# STM32H733 register map
File version: 1.2
CPU: CM7 r0p1, little endian, MPU, FPU, 4 interrupt priority bits
Registers are 32-bit, read-write, reset 0x0 unless marked. A register's access mark holds for its fields unless they carry their own. Offsets are from the block's base; [hi:lo] are bit positions; lines under a group give offsets from that group; {n}, {i} and the like mark numbered series; 'fields as' and 'values as' point back to an identical list; <NAME> marks a mode.

## ADC1 — Analog to Digital Converter
Base 0x40022000
Same registers: ADC2 0x40022100
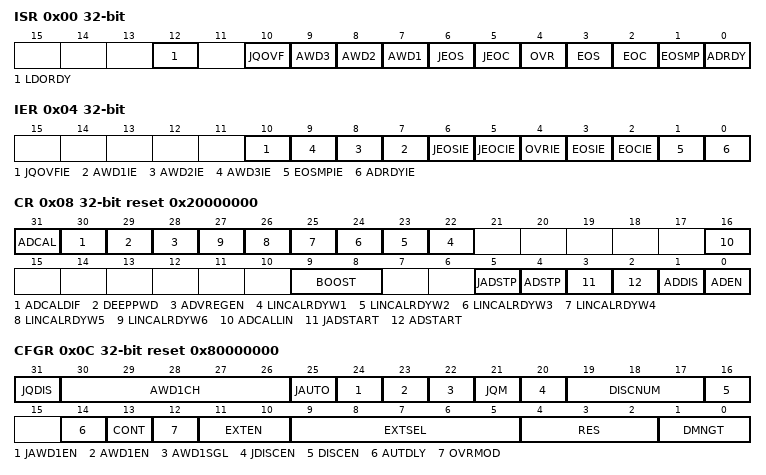
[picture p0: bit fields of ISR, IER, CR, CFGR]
0x00 ISR access per field — ADC interrupt and status register
  [12] LDORDY ro — ADC LDO output voltage ready bit This bit is set and cleared by hardware. It indicates that the ADC internal LDO output is ready and that the ADC can be enabled or calibrated. Note: Refer to for the availability of the LDO regulator.
  [10] JQOVF rw write-1-clears — Injected context queue overflow This bit is set by hardware when an Overflow of the Injected Queue of Context occurs. It is cleared by software writing 1 to it. Refer to for more information.
    on read: 0=NoOverflow (No injected context queue overflow has occurred); 1=Overflow (Injected context queue overflow has occurred) | on write: 1=Clear injected context queue overflow flag
  [n+6] AWD{n} (n=1..3) rw write-1-clears — Analog watchdog {n} flag
    on read: 0=NoEvent (No analog watchdog event occurred); 1=Event (Analog watchdog event occurred) | on write: 1=Clear analog watchdog event occurred flag
  [6] JEOS rw write-1-clears — Injected channel end of sequence flag This bit is set by hardware at the end of the conversions of all injected channels in the group. It is cleared by software writing 1 to it.
    on read: 0=NotComplete (Injected sequence is not complete); 1=Complete (Injected sequence complete) | on write: 1=Clear Injected sequence complete flag
  [5] JEOC rw write-1-clears — Injected channel end of conversion flag This bit is set by hardware at the end of each injected conversion of a channel when a new data is available in the corresponding ADC_JDRy register. It is cleared by software writing 1 to it or by reading the corresponding ADC_JDRy register
    on read: 0=NotComplete (Injected conversion is not complete); 1=Complete (Injected conversion complete) | on write: 1=Clear injected conversion complete flag
  [4] OVR rw write-1-clears — ADC overrun This bit is set by hardware when an overrun occurs on a regular channel, meaning that a new conversion has completed while the EOC flag was already set. It is cleared by software writing 1 to it.
    on read: 0=No overrun occurred; 1=Overrun occurred | on write: 1=Clear overrun occurred flag
  [3] EOS rw write-1-clears — End of regular sequence flag This bit is set by hardware at the end of the conversions of a regular sequence of channels. It is cleared by software writing 1 to it.
    on read: 0=NotComplete (Regular sequence is not complete); 1=Complete (Regular sequence complete) | on write: 1=Clear regular sequence complete flag
  [2] EOC rw write-1-clears — End of conversion flag This bit is set by hardware at the end of each regular conversion of a channel when a new data is available in the ADC_DR register. It is cleared by software writing 1 to it or by reading the ADC_DR register
    on read: 0=NotComplete (Regular conversion is not complete); 1=Complete (Regular conversion complete) | on write: 1=Clear regular conversion complete flag
  [1] EOSMP rw write-1-clears — End of sampling flag This bit is set by hardware during the conversion of any channel (only for regular channels), at the end of the sampling phase.
    on read: 0=NotEnded (End of sampling phase no yet reached); 1=Ended (End of sampling phase reached) | on write: 1=Clear end of sampling phase reached flag
  [0] ADRDY rw write-1-clears — ADC ready This bit is set by hardware after the ADC has been enabled (bit ADEN=1) and when the ADC reaches a state where it is ready to accept conversion requests. It is cleared by software writing 1 to it.
    on read: 0=NotReady (ADC is not ready to start conversion); 1=Ready (ADC is ready to start conversion) | on write: 1=Clear ADC is ready to start conversion flag
0x04 IER — ADC interrupt enable register
  [10] JQOVFIE — Injected context queue overflow interrupt enable This bit is set and cleared by software to enable/disable the Injected Context Queue Overflow interrupt. Note: The software is allowed to write this bit only when JADSTART=0 (which ensures that no injected conversion is ongoing).
    0=Disabled (Injected context queue overflow interrupt disabled); 1=Enabled (Injected context queue overflow interrupt enabled)
  [n+6] AWD{n}IE (n=1..3) — Analog watchdog {n} interrupt enable
    0=Disabled (Analog watchdog interrupt disabled); 1=Enabled (Analog watchdog interrupt enabled)
  [6] JEOSIE — End of injected sequence of conversions interrupt enable This bit is set and cleared by software to enable/disable the end of injected sequence of conversions interrupt. Note: The software is allowed to write this bit only when JADSTART=0 (which ensures that no injected conversion is ongoing).
    0=Disabled (End of injected sequence interrupt disabled); 1=Enabled (End of injected sequence interrupt enabled)
  [5] JEOCIE — End of injected conversion interrupt enable This bit is set and cleared by software to enable/disable the end of an injected conversion interrupt. Note: The software is allowed to write this bit only when JADSTART is cleared to 0 (no injected conversion is ongoing).
    0=Disabled (End of injected conversion interrupt disabled); 1=Enabled (End of injected conversion interrupt enabled)
  [4] OVRIE — Overrun interrupt enable This bit is set and cleared by software to enable/disable the Overrun interrupt of a regular conversion. Note: The software is allowed to write this bit only when ADSTART=0 (which ensures that no regular conversion is ongoing).
    0=Disabled (Overrun interrupt disabled); 1=Enabled (Overrun interrupt enabled)
  [3] EOSIE — End of regular sequence of conversions interrupt enable This bit is set and cleared by software to enable/disable the end of regular sequence of conversions interrupt. Note: The software is allowed to write this bit only when ADSTART=0 (which ensures that no regular conversion is ongoing).
    0=Disabled (End of regular sequence interrupt disabled); 1=Enabled (End of regular sequence interrupt enabled)
  [2] EOCIE — End of regular conversion interrupt enable This bit is set and cleared by software to enable/disable the end of a regular conversion interrupt. Note: The software is allowed to write this bit only when ADSTART=0 (which ensures that no regular conversion is ongoing).
    0=Disabled (End of regular conversion interrupt disabled); 1=Enabled (End of regular conversion interrupt enabled)
  [1] EOSMPIE — End of sampling flag interrupt enable for regular conversions This bit is set and cleared by software to enable/disable the end of the sampling phase interrupt for regular conversions. Note: The software is allowed to write this bit only when ADSTART=0 (which ensures that no regular conversion is ongoing).
    0=Disabled (End of regular conversion sampling phase interrupt disabled); 1=Enabled (End of regular conversion sampling phase interrupt enabled)
  [0] ADRDYIE — ADC ready interrupt enable This bit is set and cleared by software to enable/disable the ADC Ready interrupt. Note: The software is allowed to write this bit only when ADSTART=0 and JADSTART=0 (which ensures that no conversion is ongoing).
    0=Disabled (ADC ready interrupt disabled); 1=Enabled (ADC ready interrupt enabled)
0x08 CR reset 0x20000000 — ADC control register
  [31] ADCAL write-1-sets — ADC calibration This bit is set by software to start the calibration of the ADC. Program first the bit ADCALDIF to determine if this calibration applies for single-ended or differential inputs mode. It is cleared by hardware after calibration is complete. Note: The software is allowed to launch a calibration by setting ADCAL only when ADEN=0. The software is allowed to update the calibration factor by writing ADC_CALFACT only when ADEN=1 and ADSTART=0 and JADSTART=0 (ADC enabled and no conversion is ongoing)
    on read: 0=NotCalibrating (ADC calibration either not yet performed or completed); 1=Calibrating (ADC calibration in progress) | on write: 1=StartCalibration (Start the ADC calibration sequence)
  [30] ADCALDIF — Differential mode for calibration This bit is set and cleared by software to configure the single-ended or differential inputs mode for the calibration. Note: The software is allowed to write this bit only when the ADC is disabled and is not calibrating (ADCAL=0, JADSTART=0, JADSTP=0, ADSTART=0, ADSTP=0, ADDIS=0 and ADEN=0).
    0=SingleEnded (Calibration for single-ended mode); 1=Differential (Calibration for differential mode)
  [29] DEEPPWD — Deep-power-down enable This bit is set and cleared by software to put the ADC in deep-power-down mode. Note: The software is allowed to write this bit only when the ADC is disabled (ADCAL=0, JADSTART=0, JADSTP=0, ADSTART=0, ADSTP=0, ADDIS=0 and ADEN=0).
    0=PowerUp (ADC not in deep power down); 1=PowerDown (ADC in deep power down)
  [28] ADVREGEN — ADC voltage regulator enable This bits is set by software to enable the ADC voltage regulator. Before performing any operation such as launching a calibration or enabling the ADC, the ADC voltage regulator must first be enabled and the software must wait for the regulator start-up time. For more details about the ADC voltage regulator enable and disable sequences, refer to (ADVREGEN). The software can program this bitfield only when the ADC is disabled (ADCAL=0, JADSTART=0, ADSTART=0, ADSTP=0, ADDIS=0 and ADEN=0).
    0=Disabled (ADC voltage regulator disabled); 1=Enabled (ADC voltage regulator enabled)
  [n+21] LINCALRDYW{n} (n=1..6) — Linearity calibration ready Word {n}
    0=Reset (LINCALFACT Word Read); 1=Set (LINCALFACT Word Write)
  [16] ADCALLIN — Linearity calibration This bit is set and cleared by software to enable the Linearity calibration. Note: The software is allowed to write this bit only when the ADC is disabled and is not calibrating (ADCAL=0, JADSTART=0, JADSTP=0, ADSTART=0, ADSTP=0, ADDIS=0 and ADEN=0).
    0=NoLinearity (ADC calibration without linearaity calibration); 1=Linearity (ADC calibration with linearaity calibration)
  [9:8] BOOST — Boost mode control This bitfield is set and cleared by software to enable/disable the Boost mode. Note: The software is allowed to write this bit only when ADSTART=0 and JADSTART=0 (which ensures that no conversion is ongoing). When dual mode is enabled (bits DAMDF of ADCx_CCR register are not equal to zero), the BOOST bitfield of the slave ADC is no more writable and its content must be equal to the master ADC BOOST bitfield.
    0=LT6_25 (Boost mode used when ADC clock ≤ 6.25 MHz); 1=LT12_5 (Boost mode used when 6.25 MHz < ADC clock ≤ 12.5 MHz); 2=LT25 (Boost mode used when 12.5 MHz < ADC clock ≤ 25.0 MHz); 3=LT50 (Boost mode used when 25.0 MHz < ADC clock ≤ 50.0 MHz)
  [5] JADSTP write-1-sets — ADC stop of injected conversion command This bit is set by software to stop and discard an ongoing injected conversion (JADSTP Command). It is cleared by hardware when the conversion is effectively discarded and the ADC injected sequence and triggers can be re-configured. The ADC is then ready to accept a new start of injected conversions (JADSTART command). Note: The software is allowed to set JADSTP only when JADSTART=1 and ADDIS=0 (ADC is enabled and eventually converting an injected conversion and there is no pending request to disable the ADC). In auto-injection mode (JAUTO=1), setting ADSTP bit aborts both regular and injected conversions (do not use JADSTP)
    on read: 0=NotStopping (No stop command active); 1=Stopping (ADC stopping conversion) | on write: 1=StopConversion (Stop the active conversion)
  [4] ADSTP write-1-sets — ADC stop of regular conversion command This bit is set by software to stop and discard an ongoing regular conversion (ADSTP Command). It is cleared by hardware when the conversion is effectively discarded and the ADC regular sequence and triggers can be re-configured. The ADC is then ready to accept a new start of regular conversions (ADSTART command). Note: The software is allowed to set ADSTP only when ADSTART=1 and ADDIS=0 (ADC is enabled and eventually converting a regular conversion and there is no pending request to disable the ADC). In auto-injection mode (JAUTO=1), setting ADSTP bit aborts both regular and injected conversions (do not use JADSTP). In dual ADC regular simultaneous mode and interleaved mode, the bit ADSTP of the master ADC must be used to stop regular conversions. The other ADSTP bit is inactive.
    values as JADSTP
  [3] JADSTART write-1-sets — ADC start of injected conversion This bit is set by software to start ADC conversion of injected channels. Depending on the configuration bits JEXTEN, a conversion will start immediately (software trigger configuration) or once an injected hardware trigger event occurs (hardware trigger configuration). It is cleared by hardware: in single conversion mode when software trigger is selected (JEXTSEL=0x0): at the assertion of the End of Injected Conversion Sequence (JEOS) flag. in all cases: after the execution of the JADSTP command, at the same time that JADSTP is cleared by hardware. Note: The software is allowed to set JADSTART only when ADEN=1 and ADDIS=0 (ADC is enabled and there is no pending request to disable the ADC). In auto-injection mode (JAUTO=1), regular and auto-injected conversions are started by setting bit ADSTART (JADSTART must be kept cleared)
    on read: 0=NotActive (No conversion ongoing); 1=Active (ADC operating and may be converting) | on write: 1=StartConversion (Start the ADC conversion (may be delayed for hardware triggers))
  [2] ADSTART write-1-sets — ADC start of regular conversion This bit is set by software to start ADC conversion of regular channels. Depending on the configuration bits EXTEN, a conversion will start immediately (software trigger configuration) or once a regular hardware trigger event occurs (hardware trigger configuration). It is cleared by hardware: in single conversion mode (CONT=0, DISCEN=0) when software trigger is selected (EXTEN=0x0): at the assertion of the End of Regular Conversion Sequence (EOS) flag. In discontinuous conversion mode (CONT=0, DISCEN=1), when the software trigger is selected (EXTEN=0x0): at the end of conversion (EOC) flag. in all other cases: after the execution of the ADSTP command, at the same time that ADSTP is cleared by hardware. Note: The software is allowed to set ADSTART only when ADEN=1 and ADDIS=0 (ADC is enabled and there is no pending request to disable the ADC) In auto-injection mode (JAUTO=1), regular and auto-injected conversions are started by setting bit ADSTART (JADSTART must be kept cleared)
    values as JADSTART
  [1] ADDIS write-1-sets — ADC disable command This bit is set by software to disable the ADC (ADDIS command) and put it into power-down state (OFF state). It is cleared by hardware once the ADC is effectively disabled (ADEN is also cleared by hardware at this time). Note: The software is allowed to set ADDIS only when ADEN=1 and both ADSTART=0 and JADSTART=0 (which ensures that no conversion is ongoing)
    on read: 0=NotDisabling (No disable command active); 1=Disabling (ADC disabling) | on write: 1=Disable the ADC
  [0] ADEN write-1-sets — ADC enable control This bit is set by software to enable the ADC. The ADC will be effectively ready to operate once the flag ADRDY has been set. It is cleared by hardware when the ADC is disabled, after the execution of the ADDIS command. Note: The software is allowed to set ADEN only when all bits of ADC_CR registers are 0 (ADCAL=0, JADSTART=0, ADSTART=0, ADSTP=0, ADDIS=0 and ADEN=0) except for bit ADVREGEN which must be 1 (and the software must have wait for the startup time of the voltage regulator)
    on read: 0=Disabled (ADC disabled); 1=Enabled (ADC enabled) | on write: 1=Enabled (Enable the ADC)
0x0C CFGR reset 0x80000000 — ADC configuration register
  [31] JQDIS — Injected Queue disable These bits are set and cleared by software to disable the Injected Queue mechanism: Note: The software is allowed to write this bit only when ADSTART=0 and JADSTART=0 (which ensures that no regular nor injected conversion is ongoing). A set or reset of JQDIS bit causes the injected queue to be flushed and the JSQR register is cleared.
    0=Enabled (Injected Queue enabled); 1=Disabled (Injected Queue disabled)
  [30:26] AWD1CH range 0..19 — Analog watchdog 1 channel selection These bits are set and cleared by software. They select the input channel to be guarded by the analog watchdog. ..... others: Reserved, must not be used Note: The channel selected by AWD1CH must be also selected into the SQRi or JSQRi registers. The software is allowed to write these bits only when ADSTART=0 and JADSTART=0 (which ensures that no conversion is ongoing).
  [25] JAUTO — Automatic injected group conversion This bit is set and cleared by software to enable/disable automatic injected group conversion after regular group conversion. Note: The software is allowed to write this bit only when ADSTART=0 and JADSTART=0 (which ensures that no regular nor injected conversion is ongoing). When dual mode is enabled (DAMDF bits in ADCx_CCR register are not equal to zero), the bit JAUTO of the slave ADC is no more writable and its content is equal to the bit JAUTO of the master ADC.
    0=Disabled (Automatic injected group conversion disabled); 1=Enabled (Automatic injected group conversion enabled)
  [24] JAWD1EN — Analog watchdog 1 enable on injected channels This bit is set and cleared by software Note: The software is allowed to write this bit only when JADSTART=0 (which ensures that no injected conversion is ongoing).
    0=Disabled (Analog watchdog 1 disabled on injected channels); 1=Enabled (Analog watchdog 1 enabled on injected channels)
  [23] AWD1EN — Analog watchdog 1 enable on regular channels This bit is set and cleared by software Note: The software is allowed to write this bit only when ADSTART=0 (which ensures that no regular conversion is ongoing).
    0=Disabled (Analog watchdog 1 disabled on regular channels); 1=Enabled (Analog watchdog 1 enabled on regular channels)
  [22] AWD1SGL — Enable the watchdog 1 on a single channel or on all channels This bit is set and cleared by software to enable the analog watchdog on the channel identified by the AWD1CH[4:0] bits or on all the channels Note: The software is allowed to write this bit only when ADSTART=0 and JADSTART=0 (which ensures that no conversion is ongoing).
    0=All (Analog watchdog 1 enabled on all channels); 1=Single (Analog watchdog 1 enabled on single channel selected in AWD1CH)
  [21] JQM — JSQR queue mode This bit is set and cleared by software. It defines how an empty Queue is managed. Refer to for more information. Note: The software is allowed to write this bit only when JADSTART=0 (which ensures that no injected conversion is ongoing). When dual mode is enabled (DAMDF bits in ADCx_CCR register are not equal to zero), the bit JQM of the slave ADC is no more writable and its content is equal to the bit JQM of the master ADC.
    0=Mode0 (JSQR Mode 0: Queue maintains the last written configuration into JSQR); 1=Mode1 (JSQR Mode 1: An empty queue disables software and hardware triggers of the injected sequence)
  [20] JDISCEN — Discontinuous mode on injected channels This bit is set and cleared by software to enable/disable discontinuous mode on the injected channels of a group. Note: The software is allowed to write this bit only when JADSTART=0 (which ensures that no injected conversion is ongoing). It is not possible to use both auto-injected mode and discontinuous mode simultaneously: the bits DISCEN and JDISCEN must be kept cleared by software when JAUTO is set. When dual mode is enabled (bits DAMDF of ADCx_CCR register are not equal to zero), the bit JDISCEN of the slave ADC is no more writable and its content is equal to the bit JDISCEN of the master ADC.
    0=Disabled (Discontinuous mode on injected channels disabled); 1=Enabled (Discontinuous mode on injected channels enabled)
  [19:17] DISCNUM — Discontinuous mode channel count These bits are written by software to define the number of regular channels to be converted in discontinuous mode, after receiving an external trigger. ... Note: The software is allowed to write these bits only when ADSTART=0 (which ensures that no regular conversion is ongoing). When dual mode is enabled (DAMDF bits in ADCx_CCR register are not equal to zero), the bits DISCNUM[2:0] of the slave ADC are no more writable and their content is equal to the bits DISCNUM[2:0] of the master ADC.
  [16] DISCEN — Discontinuous mode for regular channels This bit is set and cleared by software to enable/disable Discontinuous mode for regular channels. Note: It is not possible to have both discontinuous mode and continuous mode enabled: it is forbidden to set both DISCEN=1 and CONT=1. It is not possible to use both auto-injected mode and discontinuous mode simultaneously: the bits DISCEN and JDISCEN must be kept cleared by software when JAUTO is set. The software is allowed to write this bit only when ADSTART=0 (which ensures that no regular conversion is ongoing). When dual mode is enabled (DAMDF bits in ADCx_CCR register are not equal to zero), the bit DISCEN of the slave ADC is no more writable and its content is equal to the bit DISCEN of the master ADC.
    0=Disabled (Discontinuous mode on regular channels disabled); 1=Enabled (Discontinuous mode on regular channels enabled)
  [14] AUTDLY — Delayed conversion mode This bit is set and cleared by software to enable/disable the Auto Delayed Conversion mode.. Note: The software is allowed to write this bit only when ADSTART=0 and JADSTART=0 (which ensures that no conversion is ongoing). When dual mode is enabled (DAMDF bits in ADCx_CCR register are not equal to zero), the bit AUTDLY of the slave ADC is no more writable and its content is equal to the bit AUTDLY of the master ADC.
    0=Off (Auto delayed conversion mode off); 1=On (Auto delayed conversion mode on)
  [13] CONT — Single / continuous conversion mode for regular conversions This bit is set and cleared by software. If it is set, regular conversion takes place continuously until it is cleared. Note: It is not possible to have both discontinuous mode and continuous mode enabled: it is forbidden to set both DISCEN=1 and CONT=1. The software is allowed to write this bit only when ADSTART=0 (which ensures that no regular conversion is ongoing). When dual mode is enabled (DAMDF bits in ADCx_CCR register are not equal to zero), the bit CONT of the slave ADC is no more writable and its content is equal to the bit CONT of the master ADC.
    0=Single conversion mode; 1=Continuous conversion mode
  [12] OVRMOD — Overrun Mode This bit is set and cleared by software and configure the way data overrun is managed. Note: The software is allowed to write this bit only when ADSTART=0 (which ensures that no regular conversion is ongoing).
    0=Preserve DR register when an overrun is detected; 1=Overwrite DR register when an overrun is detected
  [11:10] EXTEN — External trigger enable and polarity selection for regular channels These bits are set and cleared by software to select the external trigger polarity and enable the trigger of a regular group. Note: The software is allowed to write these bits only when ADSTART=0 (which ensures that no regular conversion is ongoing).
    0=Disabled (Trigger detection disabled); 1=RisingEdge (Trigger detection on the rising edge); 2=FallingEdge (Trigger detection on the falling edge); 3=BothEdges (Trigger detection on both the rising and falling edges)
  [9:5] EXTSEL — External trigger selection for regular group These bits select the external event used to trigger the start of conversion of a regular group: ... Note: The software is allowed to write these bits only when ADSTART=0 (which ensures that no regular conversion is ongoing).
    0=TIM1_CC1 (Timer 1 CC1 event); 1=TIM1_CC2 (Timer 1 CC2 event); 2=TIM1_CC3 (Timer 1 CC3 event); 3=TIM2_CC2 (Timer 2 CC2 event); 4=TIM3_TRGO (Timer 3 TRGO event); 5=TIM4_CC4 (Timer 4 CC4 event); 6=EXTI11 (EXTI line 11); 7=TIM8_TRGO (Timer 8 TRGO event); 8=TIM8_TRGO2 (Timer 8 TRGO2 event); 9=TIM1_TRGO (Timer 1 TRGO event); 10=TIM1_TRGO2 (Timer 1 TRGO2 event); 11=TIM2_TRGO (Timer 2 TRGO event); 12=TIM4_TRGO (Timer 4 TRGO event); 13=TIM6_TRGO (Timer 6 TRGO event); 14=TIM15_TRGO (Timer 15 TRGO event); 15=TIM3_CC4 (Timer 3 CC4 event); 16=HRTIM1_ADCTRG1 (HRTIM1_ADCTRG1 event); 17=HRTIM1_ADCTRG3 (HRTIM1_ADCTRG3 event); 18=LPTIM1_OUT (LPTIM1_OUT event); 19=LPTIM2_OUT (LPTIM2_OUT event); 20=LPTIM3_OUT (LPTIM3_OUT event)
  [4:2] RES — Data resolution These bits are written by software to select the resolution of the conversion. Others: Reserved, must not be used. Note: The software is allowed to write these bits only when ADSTART=0 and JADSTART=0 (which ensures that no conversion is ongoing).
    0=SixteenBit (16-bit resolution); 1=FourteenBit (14-bit resolution in legacy mode (not optimized power consumption)); 2=TwelveBit (12-bit resolution in legacy mode (not optimized power consumption)); 3=TenBit (10-bit resolution); 5=FourteenBitV (14-bit resolution); 6=TwelveBitV (12-bit resolution); 7=EightBit (8-bit resolution)
  [1:0] DMNGT — Data Management configuration This bit is set and cleared by software to select how ADC interface output data are managed. Note: The software is allowed to write this bit only when ADSTART=0 and JADSTART=0 (which ensures that no conversion is ongoing). In dual-ADC modes, this bit is not relevant and replaced by control bit DAMDF of the ADCx_CCR register.
    0=DR (Store output data in DR only); 1=DMA One Shot Mode selected; 2=DFSDM (DFSDM mode selected); 3=DMA Circular Mode selected
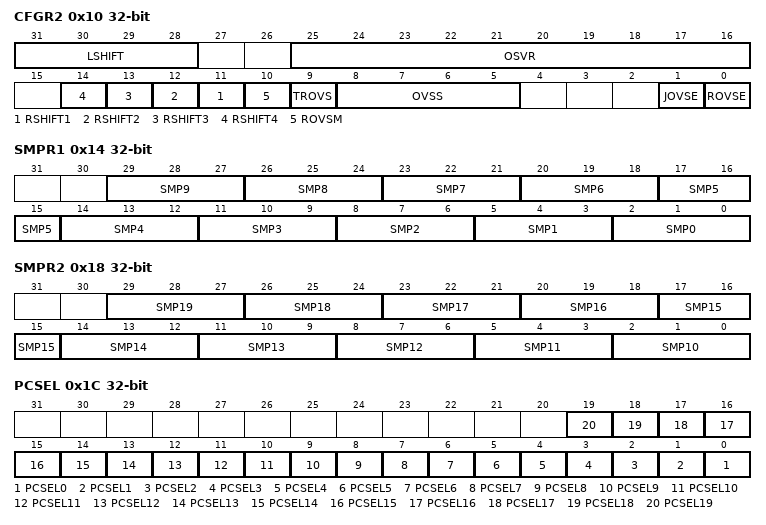
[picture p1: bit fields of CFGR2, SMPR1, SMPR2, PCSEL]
0x10 CFGR2 — ADC configuration register 2
  [31:28] LSHIFT — Left shift factor This bitfield is set and cleared by software to define the left shifting applied to the final result with or without oversampling. Note: The software is allowed to write this bit only when ADSTART=0 (which ensures that no conversion is ongoing).
  [25:16] OSVR — Oversampling ratio This bitfield is set and cleared by software to define the oversampling ratio. 2: 3x ... 1023: 1024x Note: The software is allowed to write this bit only when ADSTART=0 (which ensures that no conversion is ongoing).
  [n+10] RSHIFT{n} (n=1..4) — Right-shift data after Offset {n} correction
    0=Disabled (Right-shifting disabled); 1=Enabled (Data is right-shifted 1-bit)
  [10] ROVSM — Regular Oversampling mode This bit is set and cleared by software to select the regular oversampling mode. Note: The software is allowed to write this bit only when ADSTART=0 (which ensures that no conversion is ongoing).
    0=Continued (Oversampling is temporary stopped and continued after injection sequence); 1=Resumed (Oversampling is aborted and resumed from start after injection sequence)
  [9] TROVS — Triggered Regular Oversampling This bit is set and cleared by software to enable triggered oversampling Note: The software is allowed to write this bit only when ADSTART=0 (which ensures that no conversion is ongoing).
    0=Automatic (All oversampled conversions for a channel are run following a trigger); 1=Triggered (Each oversampled conversion for a channel needs a new trigger)
  [8:5] OVSS range 0..11 — Oversampling right shift This bitfield is set and cleared by software to define the right shifting applied to the raw oversampling result. Others: Reserved, must not be used. Note: The software is allowed to write these bits only when ADSTART=0 (which ensures that no conversion is ongoing).
  [1] JOVSE — Injected Oversampling Enable This bit is set and cleared by software to enable injected oversampling. Note: The software is allowed to write this bit only when ADSTART=0 and JADSTART=0 (which ensures that no conversion is ongoing)
    0=Disabled (Injected oversampling disabled); 1=Enabled (Injected oversampling enabled)
  [0] ROVSE — Regular Oversampling Enable This bit is set and cleared by software to enable regular oversampling. Note: The software is allowed to write this bit only when ADSTART=0 and JADSTART=0 (which ensures that no conversion is ongoing)
    0=Disabled (Regular oversampling disabled); 1=Enabled (Regular oversampling enabled)
0x14 SMPR1 — ADC sample time register 1
  [3n+2:3n] SMP{n} (n=0..9) — Channel {n} sample time selection
    0=Cycles1_5 (1.5 ADC clock cycles); 1=Cycles2_5 (2.5 ADC clock cycles); 2=Cycles8_5 (8.5 ADC clock cycles); 3=Cycles16_5 (16.5 ADC clock cycles); 4=Cycles32_5 (32.5 ADC clock cycles); 5=Cycles64_5 (64.5 ADC clock cycles); 6=Cycles387_5 (387.5 ADC clock cycles); 7=Cycles810_5 (810.5 ADC clock cycles)
0x18 SMPR2 — ADC sample time register 2
  [3n-28:3n-30] SMP{n} (n=10..19) — Channel {n} sample time selection
    values as SMPR1.SMP0
0x1C PCSEL — ADC channel preselection register
  [all] fields
    0=NotPreselected (Input channel x is not pre-selected); 1=Preselected (Pre-select input channel x)
  [n] PCSEL{n} (n=0..19) — :Channel x (VINP[i]) pre selection (x = 0 to 19) These bits are written by software to pre select the input channel at IO instance to be converted. Note: The software is allowed to write these bits only when ADSTART=0 and JADSTART=0 (which ensures that no conversion is ongoing).
0x20 LTR1 — ADC watchdog threshold register 1
  [25:0] LTR1 — Analog watchdog 1 lower threshold These bits are written by software to define the lower threshold for the analog watchdog 1. Refer to AWD2CH, AWD3CH, AWD_HTRy, AWD_LTRy, AWDy) Note: The software is allowed to write these bits only when ADSTART=0 and JADSTART=0 (which ensures that no conversion is ongoing).
0x24 HTR1 reset 0x3FFFFFF — ADC watchdog threshold register 1
  [25:0] HTR1 — Analog watchdog 1 higher threshold These bits are written by software to define the higher threshold for the analog watchdog 1. Refer to AWD2CH, AWD3CH, AWD_HTRy, AWD_LTRy, AWDy) Note: The software is allowed to write these bits only when ADSTART=0 and JADSTART=0 (which ensures that no conversion is ongoing).
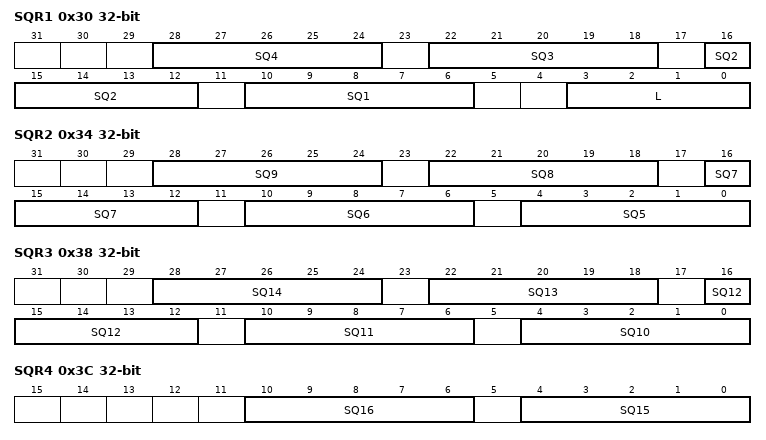
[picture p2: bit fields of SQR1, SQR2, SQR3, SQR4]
0x30 SQR1 — ADC regular sequence register 1
  [6n+4:6n] SQ{n} (n=1..4) range 0..19 — {n} conversion in regular sequence
  [3:0] L — Regular channel sequence length These bits are written by software to define the total number of conversions in the regular channel conversion sequence. ... Note: The software is allowed to write these bits only when ADSTART=0 (which ensures that no regular conversion is ongoing).
0x34 SQR2 — ADC regular sequence register 2
  [6n-26:6n-30] SQ{n} (n=5..9) range 0..19 — {n} conversion in regular sequence
0x38 SQR3 — ADC regular sequence register 3
  [6n-56:6n-60] SQ{n} (n=10..14) range 0..19 — {n} conversion in regular sequence
0x3C SQR4 — ADC regular sequence register 4
  [6n-86:6n-90] SQ{n} (n=15..16) range 0..19 — {n} conversion in regular sequence
0x40 DR ro — ADC regular Data Register
  [31:0] RDATA — Regular Data converted These bits are read-only. They contain the conversion result from the last converted regular channel. The data are left- or right-aligned as described in .
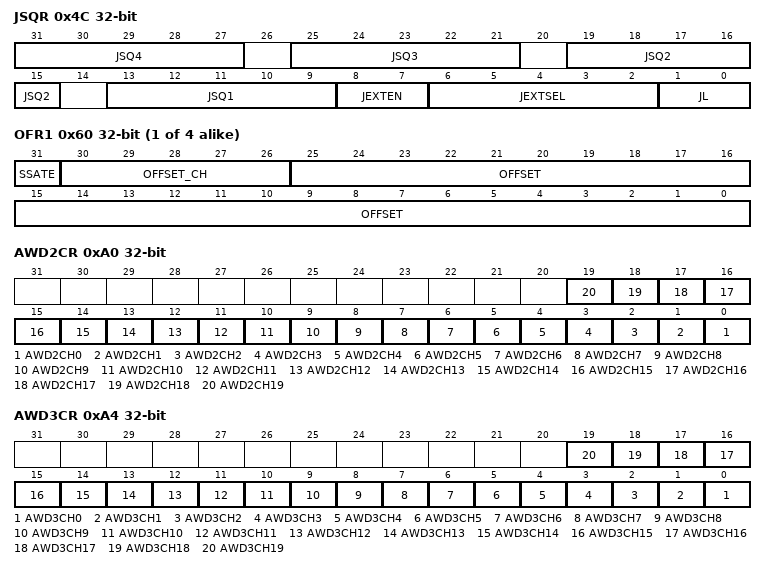
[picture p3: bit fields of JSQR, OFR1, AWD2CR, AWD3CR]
0x4C JSQR — ADC injected sequence register
  [6n+7:6n+3] JSQ{n} (n=1..4) range 0..19 — {n} conversion in injected sequence
  [8:7] JEXTEN — External trigger enable and polarity selection for injected channels These bits are set and cleared by software to select the external trigger polarity and enable the trigger of an injected group. If JQDIS=1 (queue disabled), Hardware trigger detection disabled (conversions can be launched by software Note: The software is allowed to write these bits only when JADSTART is cleared to 0 (no injected conversion is ongoing). If JQM=1 and if the Queue of Context becomes empty, the software and hardware triggers of the injected sequence are both internally disabled (refer to Queue of context for injected conversions)
    values as CFGR.EXTEN
  [6:2] JEXTSEL — External trigger selection for injected group These bits select the external event used to trigger the start of conversion of an injected group: ... Note: The software is allowed to write these bits only when JADSTART is cleared to 0 (no injected conversion is ongoing).
    0=TIM1_TRGO (Timer 1 TRGO event); 1=TIM1_CC4 (Timer 1 CC4 event); 2=TIM2_TRGO (Timer 2 TRGO event); 3=TIM2_CC1 (Timer 2 CC1 event); 4=TIM3_CC4 (Timer 3 CC4 event); 5=TIM4_TRGO (Timer 4 TRGO event); 6=EXTI15 (EXTI line 15); 7=TIM8_CC4 (Timer 8 CC4 event); 8=TIM1_TRGO2 (Timer 1 TRGO2 event); 9=TIM8_TRGO (Timer 8 TRGO event); 10=TIM8_TRGO2 (Timer 8 TRGO2 event); 11=TIM3_CC3 (Timer 3 CC3 event); 12=TIM3_TRGO (Timer 3 TRGO event); 13=TIM3_CC1 (Timer 3 CC1 event); 14=TIM6_TRGO (Timer 6 TRGO event); 15=TIM15_TRGO (Timer 15 TRGO event); 16=HRTIM1_ADCTRG2 (HRTIM1_ADCTRG2 event); 17=HRTIM1_ADCTRG4 (HRTIM1_ADCTRG4 event); 18=LPTIM1_OUT (LPTIM1_OUT event); 19=LPTIM2_OUT (LPTIM2_OUT event); 20=LPTIM3_OUT (LPTIM3_OUT event)
  [1:0] JL — Injected channel sequence length These bits are written by software to define the total number of conversions in the injected channel conversion sequence. Note: The software is allowed to write these bits only when JADSTART is cleared to 0 (no injected conversion is ongoing).
{0x5C+4i} OFR{i} (i=1..4) — ADC injected channel {i} offset register
  [31] SSATE — Signed saturation Enable This bit is written by software to enable or disable the Signed saturation feature. This bit can be enabled only for 8-bit and 16-bit data format (see alignment and offset (ADC_DR, ADC_JDRy, OFFSETy, OFFSETy_CH, OVSS, LSHIFT, RSHIFT, SSATE) for details). Note: The software is allowed to write this bit only when ADSTART=0 and JADSTART=0 (which ensures that no conversion is ongoing).
    0=Disabled (Offset is subtracted maintaining data integrity and extending result size (9-bit and 17-bit signed format)); 1=Enabled (Offset is subtracted and result is saturated to maintain result size)
  [30:26] OFFSET_CH — Channel selection for the data offset X
  [25:0] OFFSET — Data offset X for the channel programmed into bits OFFSET_CH
{0x7C+4i} JDR{i} (i=1..4) ro — ADC injected channel {i} data register
  [31:0] JDATA — Injected data These bits are read-only. They contain the conversion result from injected channel y. The data are left -or right-aligned as described in .
0xA0 AWD2CR access not given — ADC analog watchdog 2 configuration register
  [n] AWD2CH{n} (n=0..19) — Analog watchdog 2 channel selection These bits are set and cleared by software. They enable and select the input channels to be guarded by the analog watchdog 2. AWD2CH[i] = 0: ADC analog input channel-i is not monitored by AWD2 AWD2CH[i] = 1: ADC analog input channel-i is monitored by AWD2 When AWD2CH[19:0] = 000..0, the analog Watchdog 2 is disabled Note: The channels selected by AWD2CH must be also selected into the SQRi or JSQRi registers. The software is allowed to write these bits only when ADSTART=0 and JADSTART=0 (which ensures that no conversion is ongoing).
    0=NotMonitored (Input channel not monitored by AWDx); 1=Monitored (Input channel monitored by AWDx)
0xA4 AWD3CR access not given — ADC analog watchdog 3 configuration register
  [n] AWD3CH{n} (n=0..19) — Analog watchdog 3 channel selection These bits are set and cleared by software. They enable and select the input channels to be guarded by the analog watchdog 3. AWD3CH[i] = 0: ADC analog input channel-i is not monitored by AWD3 AWD3CH[i] = 1: ADC analog input channel-i is monitored by AWD3 When AWD3CH[19:0] = 000..0, the analog Watchdog 3 is disabled Note: The channels selected by AWD3CH must be also selected into the SQRi or JSQRi registers. The software is allowed to write these bits only when ADSTART=0 and JADSTART=0 (which ensures that no conversion is ongoing).
    values as AWD2CR.AWD2CH0
0xB0 LTR2 — ADC watchdog lower threshold register 2
  [25:0] LTR2 — Analog watchdog 2 lower threshold These bits are written by software to define the lower threshold for the analog watchdog 2. Refer to AWD2CH, AWD3CH, AWD_HTRy, AWD_LTRy, AWDy). Note: The software is allowed to write these bits only when ADSTART=0 and JADSTART=0 (which ensures that no conversion is ongoing).
0xB4 HTR2 reset 0x3FFFFFF — ADC watchdog higher threshold register 2
  [25:0] HTR2 — Analog watchdog 2 higher threshold These bits are written by software to define the higher threshold for the analog watchdog 2. Refer to AWD2CH, AWD3CH, AWD_HTRy, AWD_LTRy, AWDy). Note: The software is allowed to write these bits only when ADSTART=0 and JADSTART=0 (which ensures that no conversion is ongoing).
0xB8 LTR3 — ADC watchdog lower threshold register 3
  [25:0] LTR3 — Analog watchdog 3 lower threshold These bits are written by software to define the lower threshold for the analog watchdog 3. Refer to AWD2CH, AWD3CH, AWD_HTRy, AWD_LTRy, AWDy) Note: The software is allowed to write these bits only when ADSTART=0 and JADSTART=0 (which ensures that no conversion is ongoing).
0xBC HTR3 reset 0x3FFFFFF — ADC watchdog higher threshold register 3
  [25:0] HTR3 — Analog watchdog 3 higher threshold These bits are written by software to define the higher threshold for the analog watchdog 3. Refer to AWD2CH, AWD3CH, AWD_HTRy, AWD_LTRy, AWDy) Note: The software is allowed to write these bits only when ADSTART=0 and JADSTART=0 (which ensures that no conversion is ongoing).
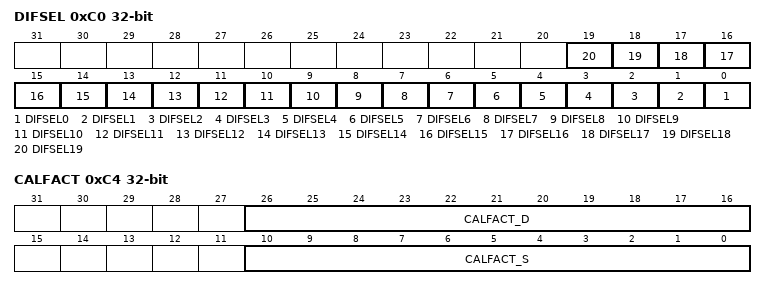
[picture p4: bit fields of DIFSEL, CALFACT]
0xC0 DIFSEL access not given — ADC differential mode selection register
  [n] DIFSEL{n} (n=0..19) — Differential mode for channel {n}
    0=SingleEnded (Input channel is configured in single-ended mode); 1=Differential (Input channel is configured in differential mode)
0xC4 CALFACT — ADC calibration factors register
  [26:16] CALFACT_D — Calibration Factors in differential mode These bits are written by hardware or by software. Once a differential inputs calibration is complete, they are updated by hardware with the calibration factors. Software can write these bits with a new calibration factor. If the new calibration factor is different from the current one stored into the analog ADC, it will then be applied once a new differential conversion is launched. Note: The software is allowed to write these bits only when ADEN=1, ADSTART=0 and JADSTART=0 (ADC is enabled and no calibration is ongoing and no conversion is ongoing).
  [10:0] CALFACT_S — Calibration Factors In Single-Ended mode These bits are written by hardware or by software. Once a single-ended inputs calibration is complete, they are updated by hardware with the calibration factors. Software can write these bits with a new calibration factor. If the new calibration factor is different from the current one stored into the analog ADC, it will then be applied once a new single-ended conversion is launched. Note: The software is allowed to write these bits only when ADEN=1, ADSTART=0 and JADSTART=0 (ADC is enabled and no calibration is ongoing and no conversion is ongoing).
0xC8 CALFACT2 — ADC calibration factor register 2
  [29:0] LINCALFACT — Linearity Calibration Factor These bits are written by hardware or by software. They hold 30-bit out of the 160-bit linearity calibration factor. Once a single-ended inputs calibration is complete, they are updated by hardware with the calibration factors. Software can write these bits with a new calibration factor. If the new calibration factor is different from the current one stored into the analog ADC, it will then be applied once a new single-ended calibration is launched. Note: The software is allowed to write these bits only when ADEN=1, ADSTART=0 and JADSTART=0 (ADC is enabled and no calibration is ongoing and no conversion is ongoing).
